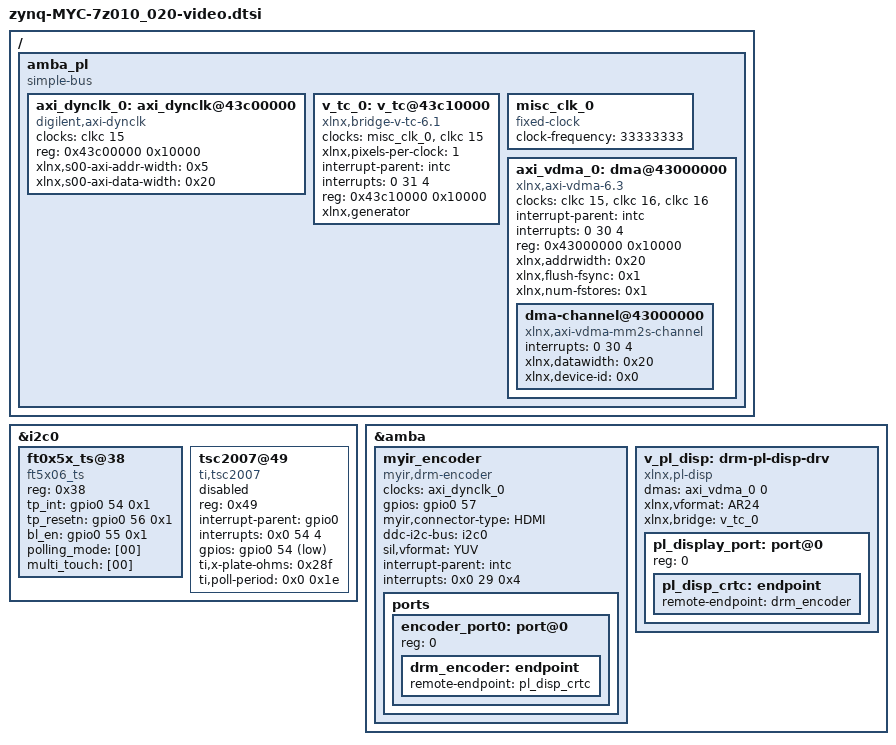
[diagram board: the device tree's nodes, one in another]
/*
 * CAUTION: This file is automatically generated by Xilinx.
 * Version:  
 * Today is: Tue Dec 25 14:02:03 2021
 */

 &i2c0 {
    // clock-frequency = <100000>;

    // sii902x@3b {
    //     compatible = "sii902x";
    //     reg = <0x3b>;
    //     interrupt-parent = <&intc>;
    //     interrupts = <0x0 29 0x4>;
    //     mode_str = "1920x1080";
    //     bits-per-pixel = <0x10>;
    //     display-color-space = <1>; //0:RGB, 1:YUV
    // };

    ft0x5x_ts@38 {
        compatible = "ft5x06_ts";
        status = "okay";
        reg = <0x38>;
        tp_int = <&gpio0 54 0x1>;
        tp_resetn = <&gpio0 56 0x1>;
        bl_en = <&gpio0 55 0x1>;
        polling_mode = [00];
        multi_touch = [00];
    };

    tsc2007@49 {
        compatible = "ti,tsc2007";
        status = "disabled";
        reg = <0x49>;
        interrupt-parent = <&gpio0>;
        interrupts = <0x0 54 4>;
        gpios = <&gpio0 54 1>;
        ti,x-plate-ohms = <0x28f>;
        ti,poll-period = <0x0 0x1e>;
    };
};

&amba {
    myir_encoder: myir_encoder  {
        compatible = "myir,drm-encoder";
        clocks = <&axi_dynclk_0>;
        gpios = <&gpio0 57 0x0>; // hdmi lcd display mode switch
        myir,connector-type = "HDMI"; // choose HDMI or LCD display mode
        ddc-i2c-bus = <&i2c0>;
        sil,vformat = "YUV"; //Sii902x video out format, should be "YUV" or "RGB", don't modify this config!
        interrupt-parent = <&intc>;
        interrupts = <0x0 29 0x4>; //Sii902x hotplug interrupt, defined in Vivado project, don't modify that unless you have change the interrupt in Vivado project!

        ports {
            #address-cells = <1>;
            #size-cells = <0>;

            encoder_port0: port@0 {
                reg = <0>;
                drm_encoder: endpoint {
                    remote-endpoint = <&pl_disp_crtc>;
                };
            };
        };
    };

	v_pl_disp: drm-pl-disp-drv {
		compatible = "xlnx,pl-disp";
		dmas = <&axi_vdma_0 0>;
		dma-names = "dma0";
		xlnx,vformat = "AR24";
		xlnx,bridge = <&v_tc_0>;
		#address-cells = <1>;
		#size-cells = <0>;
        status = "okay";

		pl_display_port: port@0 {
			reg = <0>;
			pl_disp_crtc: endpoint {
				remote-endpoint = <&drm_encoder>;
			};
		};
	};
};

/ {
	amba_pl: amba_pl {
		#address-cells = <1>;
		#size-cells = <1>;
		compatible = "simple-bus";
		ranges ;

        axi_dynclk_0: axi_dynclk@43c00000 {
            #clock-cells = <0x0>;	
			clock-names = "s00_axi_aclk";
			clocks = <&clkc 15>;
			compatible = "digilent,axi-dynclk";
			reg = <0x43c00000 0x10000>;
			xlnx,s00-axi-addr-width = <0x5>;
			xlnx,s00-axi-data-width = <0x20>;
		};
		v_tc_0: v_tc@43c10000 {
			clock-names = "clk", "s_axi_aclk";
			clocks = <&misc_clk_0>, <&clkc 15>;
            compatible = "xlnx,bridge-v-tc-6.1";
	        xlnx,pixels-per-clock = <1>;
			interrupt-names = "irq";
			interrupt-parent = <&intc>;
			interrupts = <0 31 4>;
			reg = <0x43c10000 0x10000>;
			xlnx,generator ;
		};

        /* For LCD */
		misc_clk_0: misc_clk_0 {
			#clock-cells = <0>;
			clock-frequency = <33333333>;
			compatible = "fixed-clock";
		};

		/* For HDMI */
		// misc_clk_0: misc_clk_0 {
		// 	#clock-cells = <0>;
		// 	clock-frequency = <148500000>;
		// 	compatible = "fixed-clock";
		// };

		axi_vdma_0: dma@43000000 {
			#dma-cells = <1>;
			clock-names = "s_axi_lite_aclk", "m_axi_mm2s_aclk", "m_axis_mm2s_aclk";
			clocks = <&clkc 15>, <&clkc 16>, <&clkc 16>;
			compatible = "xlnx,axi-vdma-6.3", "xlnx,axi-vdma-1.00.a";
			interrupt-names = "mm2s_introut";
			interrupt-parent = <&intc>;
			interrupts = <0 30 4>;
			reg = <0x43000000 0x10000>;
			xlnx,addrwidth = <0x20>;
			xlnx,flush-fsync = <0x1>;
			xlnx,num-fstores = <0x1>;
			dma-channel@43000000 {
				compatible = "xlnx,axi-vdma-mm2s-channel";
				interrupts = <0 30 4>;
				xlnx,datawidth = <0x20>;
				xlnx,device-id = <0x0>;
			};
		};
	};
};
